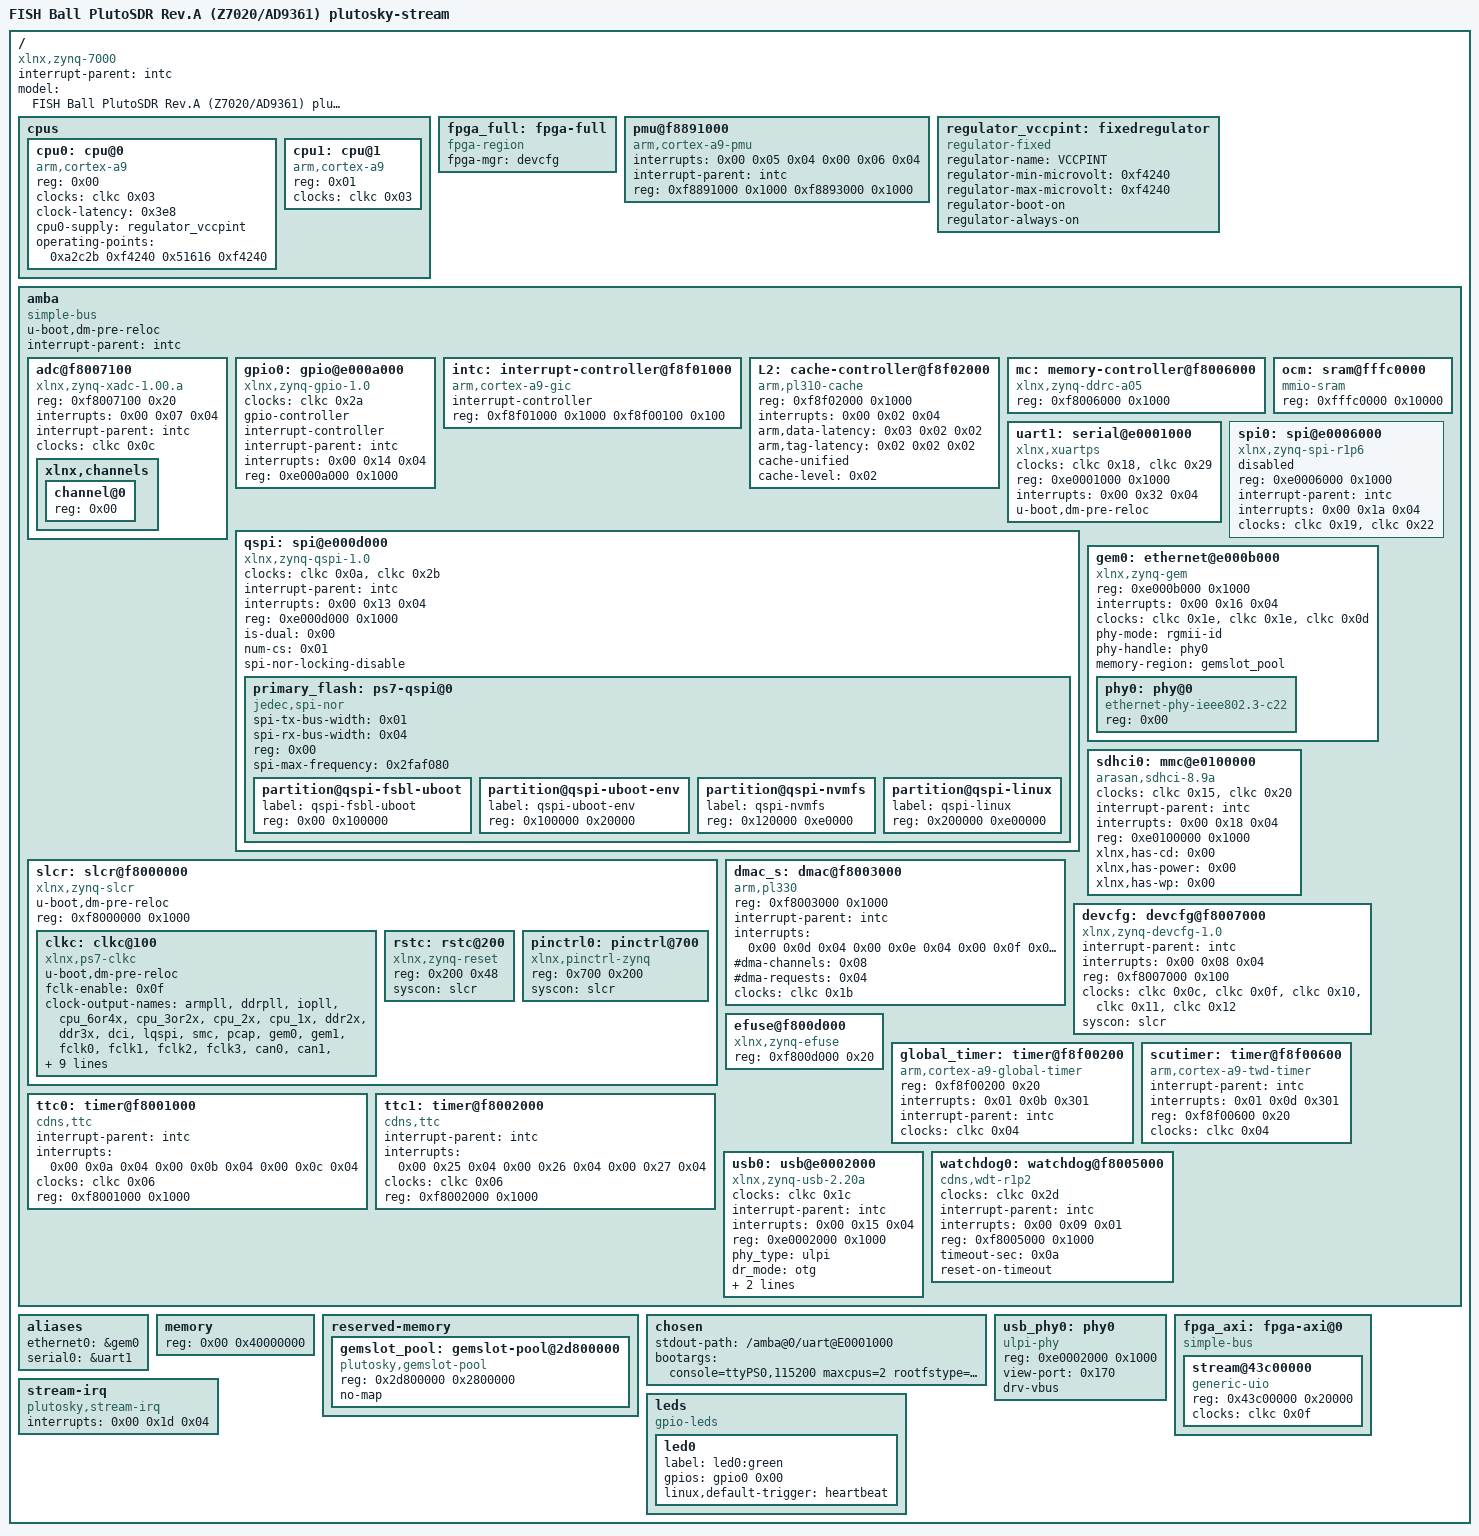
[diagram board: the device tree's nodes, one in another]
/*
 * PlutoSky 7020 device tree for plutosky-stream.
 *
 * Derived from the vendor SD-card devicetree: the ADI AD9361/DMA/DDS/mwipcore
 * nodes are gone (the PL does not provide them), the PS SPI0 that reached
 * the AD9361 over EMIO is disabled (the PL drives the SPI pins), a generic-uio
 * node covers the LiteX CSR window, and a reserved-memory pool holds the GEM
 * slot rings. Everything the vendor FSBL, u-boot and kernel depend on (DDR,
 * QSPI, UART1, GEM0, USB0, SD0) is kept.
 *
 * Build with: dtc -I dts -O dtb -o devicetree.dtb plutosky-stream.dts
 */
/dts-v1/;

/ {
	#address-cells = <0x01>;
	#size-cells = <0x01>;
	compatible = "xlnx,zynq-7000";
	interrupt-parent = <&intc>;
	model = "FISH Ball PlutoSDR Rev.A (Z7020/AD9361) plutosky-stream";

	cpus {
		#address-cells = <0x01>;
		#size-cells = <0x00>;

		cpu0: cpu@0 {
			compatible = "arm,cortex-a9";
			device_type = "cpu";
			reg = <0x00>;
			clocks = <&clkc 0x03>;
			clock-latency = <0x3e8>;
			cpu0-supply = <&regulator_vccpint>;
			operating-points = <0xa2c2b 0xf4240 0x51616 0xf4240>;
		};

		cpu1: cpu@1 {
			compatible = "arm,cortex-a9";
			device_type = "cpu";
			reg = <0x01>;
			clocks = <&clkc 0x03>;
		};
	};

	fpga_full: fpga-full {
		compatible = "fpga-region";
		fpga-mgr = <&devcfg>;
		#address-cells = <0x01>;
		#size-cells = <0x01>;
		ranges;
	};

	pmu@f8891000 {
		compatible = "arm,cortex-a9-pmu";
		interrupts = <0x00 0x05 0x04 0x00 0x06 0x04>;
		interrupt-parent = <&intc>;
		reg = <0xf8891000 0x1000 0xf8893000 0x1000>;
	};

	regulator_vccpint: fixedregulator {
		compatible = "regulator-fixed";
		regulator-name = "VCCPINT";
		regulator-min-microvolt = <0xf4240>;
		regulator-max-microvolt = <0xf4240>;
		regulator-boot-on;
		regulator-always-on;
	};

	amba: amba {
		u-boot,dm-pre-reloc;
		compatible = "simple-bus";
		#address-cells = <0x01>;
		#size-cells = <0x01>;
		interrupt-parent = <&intc>;
		ranges;

		adc@f8007100 {
			compatible = "xlnx,zynq-xadc-1.00.a";
			reg = <0xf8007100 0x20>;
			interrupts = <0x00 0x07 0x04>;
			interrupt-parent = <&intc>;
			clocks = <&clkc 0x0c>;

			xlnx,channels {
				#address-cells = <0x01>;
				#size-cells = <0x00>;

				channel@0 {
					reg = <0x00>;
				};
			};
		};

		gpio0: gpio@e000a000 {
			compatible = "xlnx,zynq-gpio-1.0";
			#gpio-cells = <0x02>;
			clocks = <&clkc 0x2a>;
			gpio-controller;
			interrupt-controller;
			#interrupt-cells = <0x02>;
			interrupt-parent = <&intc>;
			interrupts = <0x00 0x14 0x04>;
			reg = <0xe000a000 0x1000>;
		};

		intc: interrupt-controller@f8f01000 {
			compatible = "arm,cortex-a9-gic";
			#interrupt-cells = <0x03>;
			interrupt-controller;
			reg = <0xf8f01000 0x1000 0xf8f00100 0x100>;
		};

		L2: cache-controller@f8f02000 {
			compatible = "arm,pl310-cache";
			reg = <0xf8f02000 0x1000>;
			interrupts = <0x00 0x02 0x04>;
			arm,data-latency = <0x03 0x02 0x02>;
			arm,tag-latency = <0x02 0x02 0x02>;
			cache-unified;
			cache-level = <0x02>;
		};

		mc: memory-controller@f8006000 {
			compatible = "xlnx,zynq-ddrc-a05";
			reg = <0xf8006000 0x1000>;
		};

		ocm: sram@fffc0000 {
			compatible = "mmio-sram";
			reg = <0xfffc0000 0x10000>;
		};

		uart1: serial@e0001000 {
			compatible = "xlnx,xuartps", "cdns,uart-r1p8";
			status = "okay";
			clocks = <&clkc 0x18 &clkc 0x29>;
			clock-names = "uart_clk", "pclk";
			reg = <0xe0001000 0x1000>;
			interrupts = <0x00 0x32 0x04>;
			u-boot,dm-pre-reloc;
		};

		/* The vendor design reached the AD9361 SPI through EMIO from here.
		 * The plutosky-stream gateware drives the SPI pins from the PL. */
		spi0: spi@e0006000 {
			compatible = "xlnx,zynq-spi-r1p6";
			reg = <0xe0006000 0x1000>;
			status = "disabled";
			interrupt-parent = <&intc>;
			interrupts = <0x00 0x1a 0x04>;
			clocks = <&clkc 0x19 &clkc 0x22>;
			clock-names = "ref_clk", "pclk";
			#address-cells = <0x01>;
			#size-cells = <0x00>;
		};

		qspi: spi@e000d000 {
			clock-names = "ref_clk", "pclk";
			clocks = <&clkc 0x0a &clkc 0x2b>;
			compatible = "xlnx,zynq-qspi-1.0";
			status = "okay";
			interrupt-parent = <&intc>;
			interrupts = <0x00 0x13 0x04>;
			reg = <0xe000d000 0x1000>;
			#address-cells = <0x01>;
			#size-cells = <0x00>;
			is-dual = <0x00>;
			num-cs = <0x01>;
			spi-nor-locking-disable;

			primary_flash: ps7-qspi@0 {
				#address-cells = <0x01>;
				#size-cells = <0x01>;
				spi-tx-bus-width = <0x01>;
				spi-rx-bus-width = <0x04>;
				compatible = "jedec,spi-nor";
				reg = <0x00>;
				spi-max-frequency = <0x2faf080>;

				partition@qspi-fsbl-uboot {
					label = "qspi-fsbl-uboot";
					reg = <0x00 0x100000>;
				};

				partition@qspi-uboot-env {
					label = "qspi-uboot-env";
					reg = <0x100000 0x20000>;
				};

				partition@qspi-nvmfs {
					label = "qspi-nvmfs";
					reg = <0x120000 0xe0000>;
				};

				partition@qspi-linux {
					label = "qspi-linux";
					reg = <0x200000 0xe00000>;
				};
			};
		};

		gem0: ethernet@e000b000 {
			compatible = "xlnx,zynq-gem", "cdns,zynq-gem", "cdns,gem";
			reg = <0xe000b000 0x1000>;
			status = "okay";
			interrupts = <0x00 0x16 0x04>;
			clocks = <&clkc 0x1e &clkc 0x1e &clkc 0x0d>;
			clock-names = "pclk", "hclk", "tx_clk";
			#address-cells = <0x01>;
			#size-cells = <0x00>;
			phy-mode = "rgmii-id";
			phy-handle = <&phy0>;
			memory-region = <&gemslot_pool>;

			phy0: phy@0 {
				reg = <0x00>;
				compatible = "ethernet-phy-ieee802.3-c22";
			};
		};

		sdhci0: mmc@e0100000 {
			compatible = "arasan,sdhci-8.9a";
			status = "okay";
			clock-names = "clk_xin", "clk_ahb";
			clocks = <&clkc 0x15 &clkc 0x20>;
			interrupt-parent = <&intc>;
			interrupts = <0x00 0x18 0x04>;
			reg = <0xe0100000 0x1000>;
			xlnx,has-cd = <0x00>;
			xlnx,has-power = <0x00>;
			xlnx,has-wp = <0x00>;
		};

		slcr: slcr@f8000000 {
			u-boot,dm-pre-reloc;
			#address-cells = <0x01>;
			#size-cells = <0x01>;
			compatible = "xlnx,zynq-slcr", "syscon", "simple-mfd";
			reg = <0xf8000000 0x1000>;
			ranges;

			clkc: clkc@100 {
				u-boot,dm-pre-reloc;
				#clock-cells = <0x01>;
				compatible = "xlnx,ps7-clkc";
				fclk-enable = <0x0f>;
				clock-output-names = "armpll", "ddrpll", "iopll", "cpu_6or4x", "cpu_3or2x", "cpu_2x", "cpu_1x", "ddr2x", "ddr3x", "dci", "lqspi", "smc", "pcap", "gem0", "gem1", "fclk0", "fclk1", "fclk2", "fclk3", "can0", "can1", "sdio0", "sdio1", "uart0", "uart1", "spi0", "spi1", "dma", "usb0_aper", "usb1_aper", "gem0_aper", "gem1_aper", "sdio0_aper", "sdio1_aper", "spi0_aper", "spi1_aper", "can0_aper", "can1_aper", "i2c0_aper", "i2c1_aper", "uart0_aper", "uart1_aper", "gpio_aper", "lqspi_aper", "smc_aper", "swdt", "dbg_trc", "dbg_apb";
				reg = <0x100 0x100>;
				ps-clk-frequency = <0x1fca055>;
			};

			rstc: rstc@200 {
				compatible = "xlnx,zynq-reset";
				reg = <0x200 0x48>;
				#reset-cells = <0x01>;
				syscon = <&slcr>;
			};

			pinctrl0: pinctrl@700 {
				compatible = "xlnx,pinctrl-zynq";
				reg = <0x700 0x200>;
				syscon = <&slcr>;
			};
		};

		dmac_s: dmac@f8003000 {
			compatible = "arm,pl330", "arm,primecell";
			reg = <0xf8003000 0x1000>;
			interrupt-parent = <&intc>;
			interrupt-names = "abort", "dma0", "dma1", "dma2", "dma3", "dma4", "dma5", "dma6", "dma7";
			interrupts = <0x00 0x0d 0x04 0x00 0x0e 0x04 0x00 0x0f 0x04 0x00 0x10 0x04 0x00 0x11 0x04 0x00 0x28 0x04 0x00 0x29 0x04 0x00 0x2a 0x04 0x00 0x2b 0x04>;
			#dma-cells = <0x01>;
			#dma-channels = <0x08>;
			#dma-requests = <0x04>;
			clocks = <&clkc 0x1b>;
			clock-names = "apb_pclk";
		};

		devcfg: devcfg@f8007000 {
			compatible = "xlnx,zynq-devcfg-1.0";
			interrupt-parent = <&intc>;
			interrupts = <0x00 0x08 0x04>;
			reg = <0xf8007000 0x100>;
			clocks = <&clkc 0x0c &clkc 0x0f &clkc 0x10 &clkc 0x11 &clkc 0x12>;
			clock-names = "ref_clk", "fclk0", "fclk1", "fclk2", "fclk3";
			syscon = <&slcr>;
		};

		efuse@f800d000 {
			compatible = "xlnx,zynq-efuse";
			reg = <0xf800d000 0x20>;
		};

		global_timer: timer@f8f00200 {
			compatible = "arm,cortex-a9-global-timer";
			reg = <0xf8f00200 0x20>;
			interrupts = <0x01 0x0b 0x301>;
			interrupt-parent = <&intc>;
			clocks = <&clkc 0x04>;
		};

		ttc0: timer@f8001000 {
			interrupt-parent = <&intc>;
			interrupts = <0x00 0x0a 0x04 0x00 0x0b 0x04 0x00 0x0c 0x04>;
			compatible = "cdns,ttc";
			clocks = <&clkc 0x06>;
			reg = <0xf8001000 0x1000>;
		};

		ttc1: timer@f8002000 {
			interrupt-parent = <&intc>;
			interrupts = <0x00 0x25 0x04 0x00 0x26 0x04 0x00 0x27 0x04>;
			compatible = "cdns,ttc";
			clocks = <&clkc 0x06>;
			reg = <0xf8002000 0x1000>;
		};

		scutimer: timer@f8f00600 {
			interrupt-parent = <&intc>;
			interrupts = <0x01 0x0d 0x301>;
			compatible = "arm,cortex-a9-twd-timer";
			reg = <0xf8f00600 0x20>;
			clocks = <&clkc 0x04>;
		};

		usb0: usb@e0002000 {
			compatible = "xlnx,zynq-usb-2.20a", "chipidea,usb2";
			status = "okay";
			clocks = <&clkc 0x1c>;
			interrupt-parent = <&intc>;
			interrupts = <0x00 0x15 0x04>;
			reg = <0xe0002000 0x1000>;
			phy_type = "ulpi";
			dr_mode = "otg";
			xlnx,phy-reset-gpio = <&gpio0 0x2e 0x00>;
			usb-phy = <&usb_phy0>;
		};

		watchdog0: watchdog@f8005000 {
			clocks = <&clkc 0x2d>;
			compatible = "cdns,wdt-r1p2";
			interrupt-parent = <&intc>;
			interrupts = <0x00 0x09 0x01>;
			reg = <0xf8005000 0x1000>;
			timeout-sec = <0x0a>;
			status = "okay";
			reset-on-timeout;
		};
	};

	aliases {
		ethernet0 = &gem0;
		serial0 = &uart1;
	};

	memory {
		device_type = "memory";
		reg = <0x00 0x40000000>;
	};

	/* Two slot rings of 2048 slots of 9728 bytes, TX ring first at offset 0,
	 * RX ring at offset 0x1300000. 38 MiB in use inside a 40 MiB window that
	 * ends where the 256 MiB CMA area begins. no-map keeps it out of the
	 * kernel linear map so the driver can map it write-combining. */
	reserved-memory {
		#address-cells = <0x01>;
		#size-cells = <0x01>;
		ranges;

		gemslot_pool: gemslot-pool@2d800000 {
			compatible = "plutosky,gemslot-pool";
			reg = <0x2d800000 0x2800000>;
			no-map;
		};
	};

	/* u-boot's sdboot writes its own bootargs over this one. The
	 * kernel is built with CONFIG_CMDLINE_EXTEND so the uio match id survives
	 * either way. */
	chosen {
		stdout-path = "/amba@0/uart@E0001000";
		bootargs = "console=ttyPS0,115200 maxcpus=2 rootfstype=ramfs root=/dev/ram0 rw earlyprintk clk_ignore_unused uio_pdrv_genirq.of_id=generic-uio";
	};

	usb_phy0: phy0 {
		compatible = "ulpi-phy";
		#phy-cells = <0x00>;
		reg = <0xe0002000 0x1000>;
		view-port = <0x170>;
		drv-vbus;
	};

	fpga_axi: fpga-axi@0 {
		compatible = "simple-bus";
		#address-cells = <0x01>;
		#size-cells = <0x01>;
		ranges;

		/* LiteX CSR window on M_AXI_GP0, 128 KiB: the timebase, the
		 * packetizer and depacketizer registers and their bus-mapped
		 * header templates. The daemon takes exact offsets from csr.json. */
		stream@43c00000 {
			compatible = "generic-uio", "plutosky,stream-csr";
			reg = <0x43c00000 0x20000>;
			clocks = <&clkc 0x0f>;
			clock-names = "fclk0";
		};
	};

	stream-irq {
		compatible = "plutosky,stream-irq";
		interrupts = <0x00 0x1d 0x04>;
	};

	leds {
		compatible = "gpio-leds";

		led0 {
			label = "led0:green";
			gpios = <&gpio0 0x00 0x00>;
			linux,default-trigger = "heartbeat";
		};
	};
};
